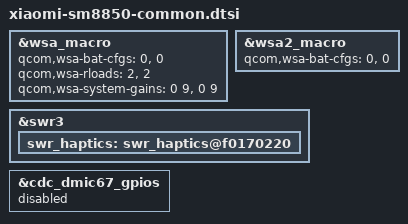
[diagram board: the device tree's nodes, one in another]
#include "lpass-audio-cdc-1.0.dtsi"
#include "canoe-lpi.dtsi"
#include "lpass-audio-bt-swr.dtsi"
#include "lpass-cdc-gpio.dtsi"
#include "canoe-audio-lpass-reg.dtsi"
#include "wsa884x.dtsi"
#include "wcd939x.dtsi"

&wsa_macro {
	qcom,wsa-bat-cfgs = <0>, <0>;
	qcom,wsa-rloads = <2>, <2>;
	qcom,wsa-system-gains = <0 9>, <0 9>;
	status = "ok";
};

&wsa2_macro {
	qcom,wsa-bat-cfgs = <0>, <0>;
	status = "ok";
};

&swr3 {
	swr_haptics: swr_haptics@f0170220 {
		status = "okay";
	};
};

&cdc_dmic67_gpios {
	status = "disabled";
};
